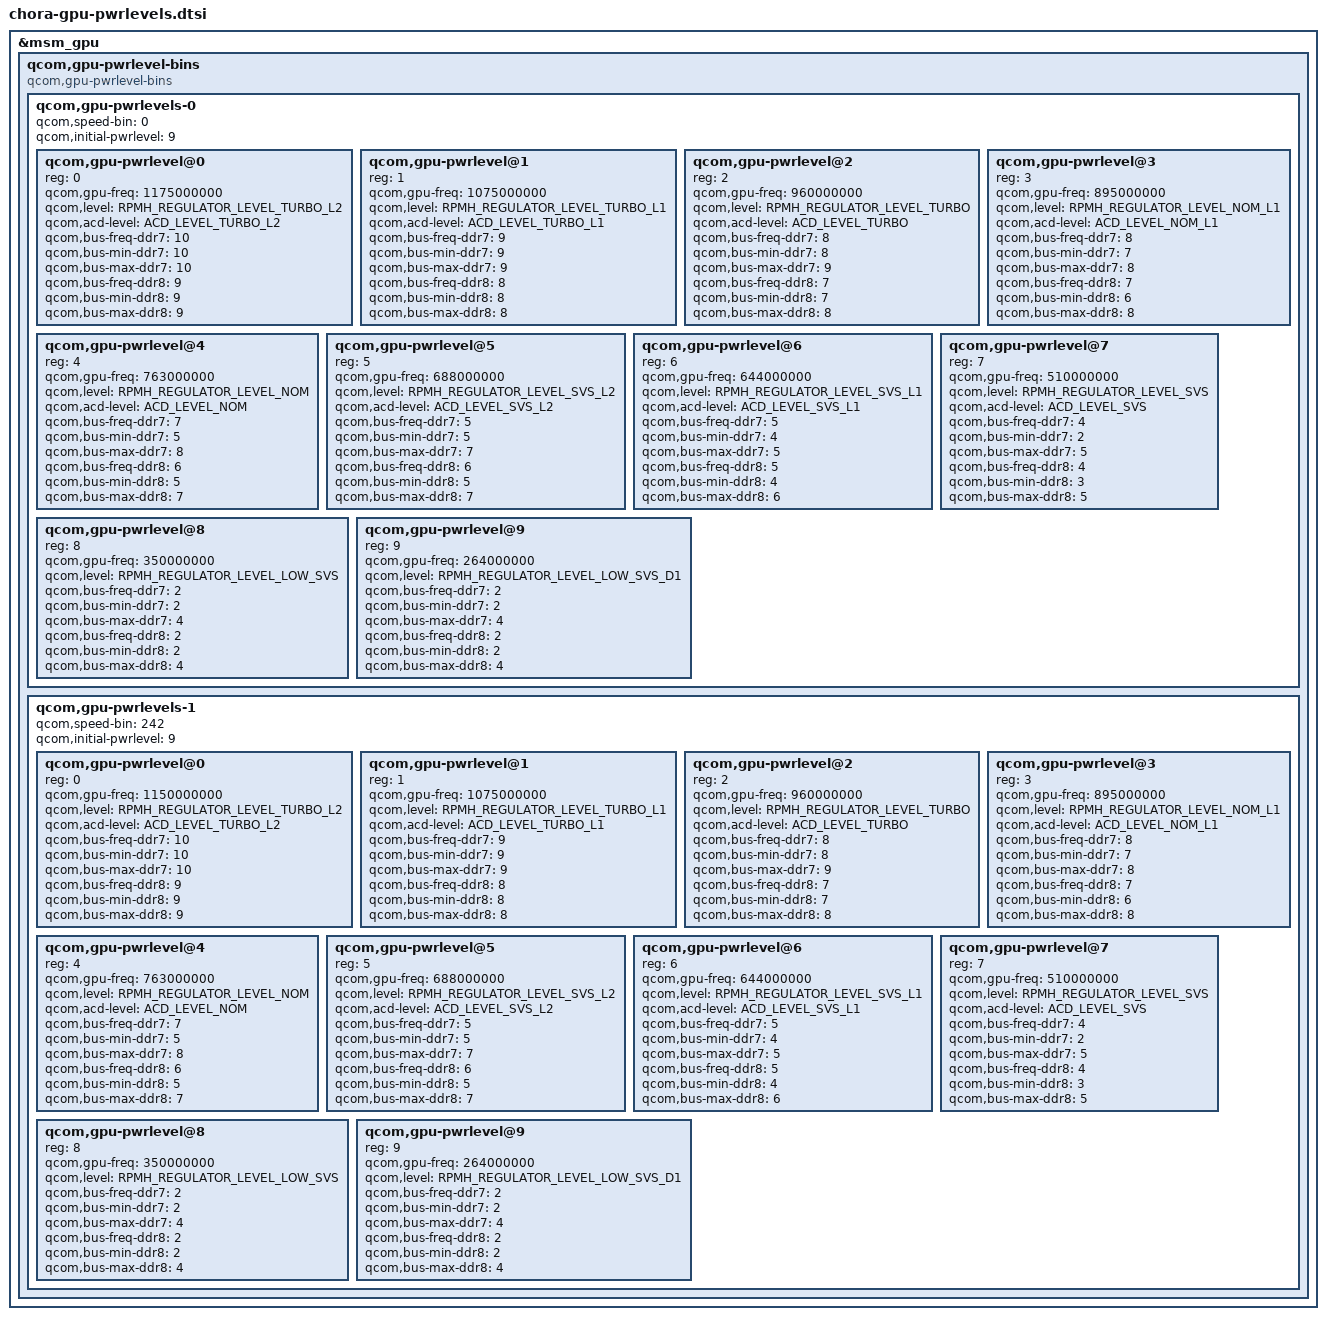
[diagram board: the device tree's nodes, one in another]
// SPDX-License-Identifier: BSD-3-Clause
/*
 * Copyright (c) Qualcomm Technologies, Inc. and/or its subsidiaries.
 */

/* ACD Control register values */
#define ACD_LEVEL_TURBO_L2  0x88295FFD
#define ACD_LEVEL_TURBO_L1  0x882A5FFD
#define ACD_LEVEL_TURBO     0x882C5FFD
#define ACD_LEVEL_NOM_L1    0xA82C5FFD
#define ACD_LEVEL_NOM       0xA82C5FFD
#define ACD_LEVEL_SVS_L2    0x882D5FFD
#define ACD_LEVEL_SVS_L1    0x882E5FFD
#define ACD_LEVEL_SVS       0x882F5FFD

&msm_gpu {
	qcom,gpu-pwrlevel-bins {
		#address-cells = <1>;
		#size-cells = <0>;

		compatible = "qcom,gpu-pwrlevel-bins";

		qcom,gpu-pwrlevels-0 {
			#address-cells = <1>;
			#size-cells = <0>;

			qcom,speed-bin = <0>;

			qcom,initial-pwrlevel = <9>;

			qcom,gpu-pwrlevel@0 {
				reg = <0>;
				qcom,gpu-freq = <1175000000>;
				qcom,level = <RPMH_REGULATOR_LEVEL_TURBO_L2>;
				qcom,acd-level = <ACD_LEVEL_TURBO_L2>;

				qcom,bus-freq-ddr7 = <10>;
				qcom,bus-min-ddr7 = <10>;
				qcom,bus-max-ddr7 = <10>;

				qcom,bus-freq-ddr8 = <9>;
				qcom,bus-min-ddr8 = <9>;
				qcom,bus-max-ddr8 = <9>;
			};

			qcom,gpu-pwrlevel@1 {
				reg = <1>;
				qcom,gpu-freq = <1075000000>;
				qcom,level = <RPMH_REGULATOR_LEVEL_TURBO_L1>;
				qcom,acd-level = <ACD_LEVEL_TURBO_L1>;

				qcom,bus-freq-ddr7 = <9>;
				qcom,bus-min-ddr7 = <9>;
				qcom,bus-max-ddr7 = <9>;

				qcom,bus-freq-ddr8 = <8>;
				qcom,bus-min-ddr8 = <8>;
				qcom,bus-max-ddr8 = <8>;
			};

			qcom,gpu-pwrlevel@2 {
				reg = <2>;
				qcom,gpu-freq = <960000000>;
				qcom,level = <RPMH_REGULATOR_LEVEL_TURBO>;
				qcom,acd-level = <ACD_LEVEL_TURBO>;

				qcom,bus-freq-ddr7 = <8>;
				qcom,bus-min-ddr7 = <8>;
				qcom,bus-max-ddr7 = <9>;

				qcom,bus-freq-ddr8 = <7>;
				qcom,bus-min-ddr8 = <7>;
				qcom,bus-max-ddr8 = <8>;
			};

			qcom,gpu-pwrlevel@3 {
				reg = <3>;
				qcom,gpu-freq = <895000000>;
				qcom,level = <RPMH_REGULATOR_LEVEL_NOM_L1>;
				qcom,acd-level = <ACD_LEVEL_NOM_L1>;

				qcom,bus-freq-ddr7 = <8>;
				qcom,bus-min-ddr7 = <7>;
				qcom,bus-max-ddr7 = <8>;

				qcom,bus-freq-ddr8 = <7>;
				qcom,bus-min-ddr8 = <6>;
				qcom,bus-max-ddr8 = <8>;
			};

			qcom,gpu-pwrlevel@4 {
				reg = <4>;
				qcom,gpu-freq = <763000000>;
				qcom,level = <RPMH_REGULATOR_LEVEL_NOM>;
				qcom,acd-level = <ACD_LEVEL_NOM>;

				qcom,bus-freq-ddr7 = <7>;
				qcom,bus-min-ddr7 = <5>;
				qcom,bus-max-ddr7 = <8>;

				qcom,bus-freq-ddr8 = <6>;
				qcom,bus-min-ddr8 = <5>;
				qcom,bus-max-ddr8 = <7>;
			};

			qcom,gpu-pwrlevel@5 {
				reg = <5>;
				qcom,gpu-freq = <688000000>;
				qcom,level = <RPMH_REGULATOR_LEVEL_SVS_L2>;
				qcom,acd-level = <ACD_LEVEL_SVS_L2>;

				qcom,bus-freq-ddr7 = <5>;
				qcom,bus-min-ddr7 = <5>;
				qcom,bus-max-ddr7 = <7>;

				qcom,bus-freq-ddr8 = <6>;
				qcom,bus-min-ddr8 = <5>;
				qcom,bus-max-ddr8 = <7>;
			};

			qcom,gpu-pwrlevel@6 {
				reg = <6>;
				qcom,gpu-freq = <644000000>;
				qcom,level = <RPMH_REGULATOR_LEVEL_SVS_L1>;
				qcom,acd-level = <ACD_LEVEL_SVS_L1>;

				qcom,bus-freq-ddr7 = <5>;
				qcom,bus-min-ddr7 = <4>;
				qcom,bus-max-ddr7 = <5>;

				qcom,bus-freq-ddr8 = <5>;
				qcom,bus-min-ddr8 = <4>;
				qcom,bus-max-ddr8 = <6>;
			};

			qcom,gpu-pwrlevel@7 {
				reg = <7>;
				qcom,gpu-freq = <510000000>;
				qcom,level = <RPMH_REGULATOR_LEVEL_SVS>;
				qcom,acd-level = <ACD_LEVEL_SVS>;

				qcom,bus-freq-ddr7 = <4>;
				qcom,bus-min-ddr7 = <2>;
				qcom,bus-max-ddr7 = <5>;

				qcom,bus-freq-ddr8 = <4>;
				qcom,bus-min-ddr8 = <3>;
				qcom,bus-max-ddr8 = <5>;
			};

			qcom,gpu-pwrlevel@8 {
				reg = <8>;
				qcom,gpu-freq = <350000000>;
				qcom,level = <RPMH_REGULATOR_LEVEL_LOW_SVS>;

				qcom,bus-freq-ddr7 = <2>;
				qcom,bus-min-ddr7 = <2>;
				qcom,bus-max-ddr7 = <4>;

				qcom,bus-freq-ddr8 = <2>;
				qcom,bus-min-ddr8 = <2>;
				qcom,bus-max-ddr8 = <4>;
			};

			qcom,gpu-pwrlevel@9 {
				reg = <9>;
				qcom,gpu-freq = <264000000>;
				qcom,level = <RPMH_REGULATOR_LEVEL_LOW_SVS_D1>;

				qcom,bus-freq-ddr7 = <2>;
				qcom,bus-min-ddr7 = <2>;
				qcom,bus-max-ddr7 = <4>;

				qcom,bus-freq-ddr8 = <2>;
				qcom,bus-min-ddr8 = <2>;
				qcom,bus-max-ddr8 = <4>;
			};
		};

		qcom,gpu-pwrlevels-1 {
			#address-cells = <1>;
			#size-cells = <0>;

			qcom,speed-bin = <242>;

			qcom,initial-pwrlevel = <9>;

			qcom,gpu-pwrlevel@0 {
				reg = <0>;
				qcom,gpu-freq = <1150000000>;
				qcom,level = <RPMH_REGULATOR_LEVEL_TURBO_L2>;
				qcom,acd-level = <ACD_LEVEL_TURBO_L2>;

				qcom,bus-freq-ddr7 = <10>;
				qcom,bus-min-ddr7 = <10>;
				qcom,bus-max-ddr7 = <10>;

				qcom,bus-freq-ddr8 = <9>;
				qcom,bus-min-ddr8 = <9>;
				qcom,bus-max-ddr8 = <9>;
			};

			qcom,gpu-pwrlevel@1 {
				reg = <1>;
				qcom,gpu-freq = <1075000000>;
				qcom,level = <RPMH_REGULATOR_LEVEL_TURBO_L1>;
				qcom,acd-level = <ACD_LEVEL_TURBO_L1>;

				qcom,bus-freq-ddr7 = <9>;
				qcom,bus-min-ddr7 = <9>;
				qcom,bus-max-ddr7 = <9>;

				qcom,bus-freq-ddr8 = <8>;
				qcom,bus-min-ddr8 = <8>;
				qcom,bus-max-ddr8 = <8>;
			};

			qcom,gpu-pwrlevel@2 {
				reg = <2>;
				qcom,gpu-freq = <960000000>;
				qcom,level = <RPMH_REGULATOR_LEVEL_TURBO>;
				qcom,acd-level = <ACD_LEVEL_TURBO>;

				qcom,bus-freq-ddr7 = <8>;
				qcom,bus-min-ddr7 = <8>;
				qcom,bus-max-ddr7 = <9>;

				qcom,bus-freq-ddr8 = <7>;
				qcom,bus-min-ddr8 = <7>;
				qcom,bus-max-ddr8 = <8>;
			};

			qcom,gpu-pwrlevel@3 {
				reg = <3>;
				qcom,gpu-freq = <895000000>;
				qcom,level = <RPMH_REGULATOR_LEVEL_NOM_L1>;
				qcom,acd-level = <ACD_LEVEL_NOM_L1>;

				qcom,bus-freq-ddr7 = <8>;
				qcom,bus-min-ddr7 = <7>;
				qcom,bus-max-ddr7 = <8>;

				qcom,bus-freq-ddr8 = <7>;
				qcom,bus-min-ddr8 = <6>;
				qcom,bus-max-ddr8 = <8>;
			};

			qcom,gpu-pwrlevel@4 {
				reg = <4>;
				qcom,gpu-freq = <763000000>;
				qcom,level = <RPMH_REGULATOR_LEVEL_NOM>;
				qcom,acd-level = <ACD_LEVEL_NOM>;

				qcom,bus-freq-ddr7 = <7>;
				qcom,bus-min-ddr7 = <5>;
				qcom,bus-max-ddr7 = <8>;

				qcom,bus-freq-ddr8 = <6>;
				qcom,bus-min-ddr8 = <5>;
				qcom,bus-max-ddr8 = <7>;
			};

			qcom,gpu-pwrlevel@5 {
				reg = <5>;
				qcom,gpu-freq = <688000000>;
				qcom,level = <RPMH_REGULATOR_LEVEL_SVS_L2>;
				qcom,acd-level = <ACD_LEVEL_SVS_L2>;

				qcom,bus-freq-ddr7 = <5>;
				qcom,bus-min-ddr7 = <5>;
				qcom,bus-max-ddr7 = <7>;

				qcom,bus-freq-ddr8 = <6>;
				qcom,bus-min-ddr8 = <5>;
				qcom,bus-max-ddr8 = <7>;
			};

			qcom,gpu-pwrlevel@6 {
				reg = <6>;
				qcom,gpu-freq = <644000000>;
				qcom,level = <RPMH_REGULATOR_LEVEL_SVS_L1>;
				qcom,acd-level = <ACD_LEVEL_SVS_L1>;

				qcom,bus-freq-ddr7 = <5>;
				qcom,bus-min-ddr7 = <4>;
				qcom,bus-max-ddr7 = <5>;

				qcom,bus-freq-ddr8 = <5>;
				qcom,bus-min-ddr8 = <4>;
				qcom,bus-max-ddr8 = <6>;
			};

			qcom,gpu-pwrlevel@7 {
				reg = <7>;
				qcom,gpu-freq = <510000000>;
				qcom,level = <RPMH_REGULATOR_LEVEL_SVS>;
				qcom,acd-level = <ACD_LEVEL_SVS>;

				qcom,bus-freq-ddr7 = <4>;
				qcom,bus-min-ddr7 = <2>;
				qcom,bus-max-ddr7 = <5>;

				qcom,bus-freq-ddr8 = <4>;
				qcom,bus-min-ddr8 = <3>;
				qcom,bus-max-ddr8 = <5>;
			};

			qcom,gpu-pwrlevel@8 {
				reg = <8>;
				qcom,gpu-freq = <350000000>;
				qcom,level = <RPMH_REGULATOR_LEVEL_LOW_SVS>;

				qcom,bus-freq-ddr7 = <2>;
				qcom,bus-min-ddr7 = <2>;
				qcom,bus-max-ddr7 = <4>;

				qcom,bus-freq-ddr8 = <2>;
				qcom,bus-min-ddr8 = <2>;
				qcom,bus-max-ddr8 = <4>;
			};

			qcom,gpu-pwrlevel@9 {
				reg = <9>;
				qcom,gpu-freq = <264000000>;
				qcom,level = <RPMH_REGULATOR_LEVEL_LOW_SVS_D1>;

				qcom,bus-freq-ddr7 = <2>;
				qcom,bus-min-ddr7 = <2>;
				qcom,bus-max-ddr7 = <4>;

				qcom,bus-freq-ddr8 = <2>;
				qcom,bus-min-ddr8 = <2>;
				qcom,bus-max-ddr8 = <4>;
			};
		};
	};
};
